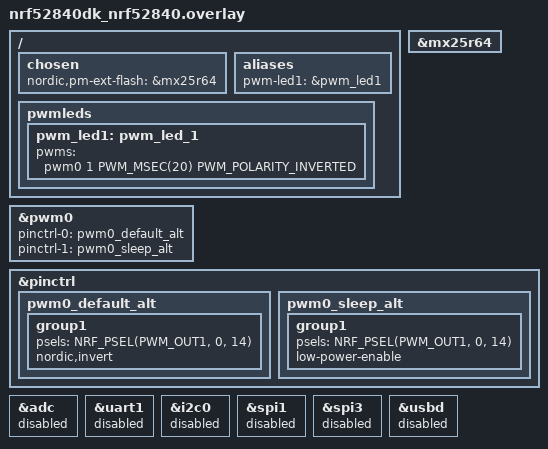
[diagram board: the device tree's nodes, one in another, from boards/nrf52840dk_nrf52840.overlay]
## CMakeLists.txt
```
#
#  Copyright (c) 2025 Nordic Semiconductor ASA
#
#  SPDX-License-Identifier: LicenseRef-Nordic-5-Clause
#


cmake_minimum_required(VERSION 3.20.0)

find_package(Zephyr HINTS $ENV{ZEPHYR_BASE})

project(matter-closure)

# Enable GNU STD support.
include(${ZEPHYR_CONNECTEDHOMEIP_MODULE_DIR}/config/nrfconnect/app/enable-gnu-std.cmake)

# NORDIC SDK APP START

# Include all source files that are located in the Matter common directory.
include(${ZEPHYR_NRF_MODULE_DIR}/samples/matter/common/cmake/source_common.cmake)

# Include Data Model utils
include(${ZEPHYR_NRF_MODULE_DIR}/samples/matter/common/cmake/data_model.cmake)

include(${ZEPHYR_NRF_MODULE_DIR}/samples/matter/common/cmake/zap_helpers.cmake)
ncs_get_zap_parent_dir(ZAP_PARENT_DIR)

target_include_directories(app PRIVATE
  src
  ${ZEPHYR_NRF_MODULE_DIR}/samples/matter/common/src/util
  ${ZAP_PARENT_DIR}
)

target_sources(app PRIVATE
  src/app_task.cpp
  src/main.cpp
  src/closure_manager.cpp
  src/closure_control_endpoint.cpp
  src/garage_door_impl.cpp
  src/persistent_percent.cpp
)

ncs_configure_data_model()
# NORDIC SDK APP END
```

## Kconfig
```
#
# Copyright (c) 2025 Nordic Semiconductor
#
# SPDX-License-Identifier: LicenseRef-Nordic-5-Clause
#
mainmenu "Matter nRF Connect Closure Example Application"

# Sample configuration used for Thread networking
if OPENTHREAD

choice OPENTHREAD_NORDIC_LIBRARY_CONFIGURATION
	default OPENTHREAD_NORDIC_LIBRARY_FTD
endchoice

choice OPENTHREAD_DEVICE_TYPE
	default OPENTHREAD_FTD
endchoice

endif # OPENTHREAD

config CHIP_WIFI
	default y if SHIELD_NRF7002EB2
	select DEPRECATED if SOC_SERIES_NRF53

source "$(ZEPHYR_CONNECTEDHOMEIP_MODULE_DIR)/config/nrfconnect/chip-module/Kconfig.features"
source "$(ZEPHYR_CONNECTEDHOMEIP_MODULE_DIR)/config/nrfconnect/chip-module/Kconfig.defaults"
source "$(ZEPHYR_NRF_MODULE_DIR)/samples/matter/common/src/Kconfig"
source "Kconfig.zephyr"
```

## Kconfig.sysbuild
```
#
# Copyright (c) 2025 Nordic Semiconductor ASA
#
# SPDX-License-Identifier: LicenseRef-Nordic-5-Clause
#

#### Radio core selection
config NRF_DEFAULT_IPC_RADIO
	default y

# Enable IEEE802.15.4 serialization to network core
# This config automatically pulls in the `overlay-802154.conf` in the ipc_radio image
config NETCORE_IPC_RADIO_IEEE802154
	default y if SOC_SERIES_NRF53

# Enable Bluetooth serialization to network core
# This config automatically pulls in the `overlay-bt_hci_ipc.conf` in the ipc_radio image
config NETCORE_IPC_RADIO_BT_HCI_IPC
	default y if SOC_SERIES_NRF53

#### Bootloader
choice BOOTLOADER
	default BOOTLOADER_MCUBOOT
endchoice

if BOOTLOADER_MCUBOOT

#### DFU multi-image support
config DFU_MULTI_IMAGE_PACKAGE_BUILD
	default y

config DFU_MULTI_IMAGE_PACKAGE_APP
	default y

#### DFU network core configuration
if SOC_SERIES_NRF53

choice MCUBOOT_MODE
	default MCUBOOT_MODE_OVERWRITE_ONLY
endchoice

choice BOOT_SIGNATURE_TYPE
	default BOOT_SIGNATURE_TYPE_RSA
endchoice

config SECURE_BOOT_NETCORE
	default y

config NETCORE_APP_UPDATE
	default y

config DFU_MULTI_IMAGE_PACKAGE_NET
	default y

config MCUBOOT_NRF53_MULTI_IMAGE_UPDATE
	default y if NETCORE_APP_UPDATE

endif # SOC_SERIES_NRF53

endif # BOOTLOADER_MCUBOOT

#### Enable generating factory data
config MATTER_FACTORY_DATA_GENERATE
	default y

source "share/sysbuild/Kconfig"
```

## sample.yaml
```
sample:
  description: Matter Closure sample
  name: Matter Closure
common:
  tags:
    - sysbuild
    - ci_samples_matter
tests:
  sample.matter.closure.debug:
    sysbuild: true
    build_only: true
    integration_platforms:
      - nrf54l15dk/nrf54l15/cpuapp
    platform_allow:
      - nrf52840dk/nrf52840
      - nrf5340dk/nrf5340/cpuapp
      - nrf54l15dk/nrf54l15/cpuapp
      - nrf54lm20dk/nrf54lm20b/cpuapp
      - nrf54lm20dk/nrf54lm20a/cpuapp
  sample.matter.closure.release:
    sysbuild: true
    build_only: true
    extra_args:
      - FILE_SUFFIX=release
    integration_platforms:
      - nrf54l15dk/nrf54l15/cpuapp
    platform_allow:
      - nrf52840dk/nrf52840
      - nrf5340dk/nrf5340/cpuapp
      - nrf54l15dk/nrf54l15/cpuapp
      - nrf54lm20dk/nrf54lm20b/cpuapp
      - nrf54lm20dk/nrf54lm20a/cpuapp
  sample.matter.closure.nrf7002eb2.debug:
    sysbuild: true
    build_only: true
    extra_args:
      - closure_SHIELD=nrf7002eb2
      - SB_CONFIG_WIFI_NRF70=y
    integration_platforms:
      - nrf54lm20dk/nrf54lm20b/cpuapp
    platform_allow:
      - nrf54lm20dk/nrf54lm20b/cpuapp
      - nrf54lm20dk/nrf54lm20a/cpuapp
  sample.matter.closure.nrf7002eb2.release:
    sysbuild: true
    build_only: true
    extra_args:
      - FILE_SUFFIX=release
      - SB_CONFIG_BOOTLOADER_MCUBOOT=y
      - closure_SHIELD=nrf7002eb2
      - SB_CONFIG_WIFI_NRF70=y
    integration_platforms:
      - nrf54lm20dk/nrf54lm20b/cpuapp
    platform_allow:
      - nrf54lm20dk/nrf54lm20b/cpuapp
      - nrf54lm20dk/nrf54lm20a/cpuapp
  sample.matter.closure.release.internal:
    sysbuild: true
    build_only: true
    extra_args:
      - FILE_SUFFIX=internal
      - closure_EXTRA_CONF_FILE=prj_release.conf
    integration_platforms:
      - nrf54lm20dk/nrf54lm20b/cpuapp
      - nrf54lm20dk/nrf54lm20a/cpuapp
    platform_allow:
      - nrf54lm20dk/nrf54lm20b/cpuapp
      - nrf54lm20dk/nrf54lm20a/cpuapp
```

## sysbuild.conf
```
#
# Copyright (c) 2025 Nordic Semiconductor
#
# SPDX-License-Identifier: LicenseRef-Nordic-5-Clause
#

SB_CONFIG_MATTER=y
```

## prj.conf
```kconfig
#
# Copyright (c) 2025 Nordic Semiconductor ASA
#
# SPDX-License-Identifier: LicenseRef-Nordic-5-Clause
#

# This sample uses Kconfig.defaults to set options common for all
# samples. This file should contain only options specific for this sample
# or overrides of default values.

# Enable CHIP
CONFIG_CHIP=y
CONFIG_CHIP_PROJECT_CONFIG="src/chip_project_config.h"
CONFIG_CHIP_DEVICE_PRODUCT_NAME="Matter Closure"

# Configure ZAP file name
CONFIG_NCS_SAMPLE_MATTER_ZAP_FILE_PATH="${APPLICATION_CONFIG_DIR}/src/default_zap/closure.zap"

# 32768 == 0x8000 (example Product ID added temporaly,
# but it must be changed with proper PID from the list:
# https://github.com/project-chip/connectedhomeip/blob/482e6fd03196a6de45465a90003947ef4b86e0b1/docs/examples/discussion/PID_allocation_for_example_apps.md)
CONFIG_CHIP_DEVICE_PRODUCT_ID=32768
CONFIG_STD_CPP17=y

# Enable Matter pairing automatically on application start.
CONFIG_CHIP_ENABLE_PAIRING_AUTOSTART=y

# Enable Matter extended announcement and increase duration to 1 hour.
CONFIG_CHIP_BLE_EXT_ADVERTISING=y
CONFIG_CHIP_BLE_ADVERTISING_DURATION=60

# Add support for LEDs and buttons on Nordic development kits
CONFIG_DK_LIBRARY=y
CONFIG_PWM=y

# Bluetooth Low Energy configuration
CONFIG_BT_DEVICE_NAME="MatterClosure"

# Other settings
CONFIG_THREAD_NAME=y
CONFIG_MPU_STACK_GUARD=y
CONFIG_RESET_ON_FATAL_ERROR=n
CONFIG_CHIP_LIB_SHELL=y
CONFIG_NCS_SAMPLE_MATTER_TEST_SHELL=y

# Disable NFC onboarding
CONFIG_CHIP_NFC_ONBOARDING_PAYLOAD=n

# Reduce application size
CONFIG_USE_SEGGER_RTT=n

#Enable Persistent Storage
CONFIG_NCS_SAMPLE_MATTER_PERSISTENT_STORAGE=y
```

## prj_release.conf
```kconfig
#
# Copyright (c) 2025 Nordic Semiconductor ASA
#
# SPDX-License-Identifier: LicenseRef-Nordic-5-Clause
#

# This sample uses Kconfig.defaults to set options common for all
# samples. This file should contain only options specific for this sample
# or overrides of default values.

# Enable CHIP
CONFIG_CHIP=y
CONFIG_CHIP_PROJECT_CONFIG="src/chip_project_config.h"
CONFIG_CHIP_DEVICE_PRODUCT_NAME="Matter Closure"

# Configure ZAP file name
CONFIG_NCS_SAMPLE_MATTER_ZAP_FILE_PATH="${APPLICATION_CONFIG_DIR}/src/default_zap/closure.zap"

# 32768 == 0x8000 (example Product ID added temporaly,
# but it must be changed with proper PID from the list:
# https://github.com/project-chip/connectedhomeip/blob/482e6fd03196a6de45465a90003947ef4b86e0b1/docs/examples/discussion/PID_allocation_for_example_apps.md)
CONFIG_CHIP_DEVICE_PRODUCT_ID=32768
CONFIG_STD_CPP17=y

# Enable Matter pairing automatically on application start.
CONFIG_CHIP_ENABLE_PAIRING_AUTOSTART=y

# Enable Matter extended announcement and increase duration to 1 hour.
CONFIG_CHIP_BLE_EXT_ADVERTISING=y
CONFIG_CHIP_BLE_ADVERTISING_DURATION=60

# Add support for LEDs and buttons on Nordic development kits
CONFIG_DK_LIBRARY=y
CONFIG_PWM=y

# Bluetooth Low Energy configuration
CONFIG_BT_DEVICE_NAME="MatterClosure"

# Enable system reset on fatal error
CONFIG_RESET_ON_FATAL_ERROR=y

# Disable all debug features
CONFIG_USE_SEGGER_RTT=n
CONFIG_SHELL=n
CONFIG_OPENTHREAD_SHELL=n
CONFIG_CHIP_LIB_SHELL=n
CONFIG_CONSOLE=n
CONFIG_UART_CONSOLE=n
CONFIG_SERIAL=n
CONFIG_LOG=n
CONFIG_LOG_MODE_MINIMAL=n
CONFIG_ASSERT_VERBOSE=n
CONFIG_ASSERT_NO_FILE_INFO=y
CONFIG_PRINTK=n
CONFIG_PRINTK_SYNC=n
CONFIG_THREAD_NAME=n
CONFIG_BOOT_BANNER=n

# Disable NFC onboarding
CONFIG_CHIP_NFC_ONBOARDING_PAYLOAD=n

# Enable Factory Data feature
CONFIG_CHIP_FACTORY_DATA=y
CONFIG_CHIP_FACTORY_DATA_BUILD=y

# Enable Watchdog
CONFIG_NCS_SAMPLE_MATTER_WATCHDOG=y

# Enable LTO to decrease the flash usage.
CONFIG_LTO=y
CONFIG_ISR_TABLES_LOCAL_DECLARATION=y

#Enable Persistent Storage
CONFIG_NCS_SAMPLE_MATTER_PERSISTENT_STORAGE=y
```

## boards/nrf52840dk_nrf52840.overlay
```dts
/*
 * Copyright (c) 2025 Nordic Semiconductor ASA
 *
 * SPDX-License-Identifier: LicenseRef-Nordic-5-Clause
 */

#include <samples/matter/nrf52840_partitions.dtsi>

/ {
	chosen {
		nordic,pm-ext-flash = &mx25r64;
	};

	aliases {
		pwm-led1 = &pwm_led1;
	};

	pwmleds {
		pwm_led1: pwm_led_1 {
			pwms = <&pwm0 1 PWM_MSEC(20) PWM_POLARITY_INVERTED>;
		};
	};
};

&mx25r64 {
	status = "okay";
};

&pwm0 {
	pinctrl-0 = <&pwm0_default_alt>;
	pinctrl-1 = <&pwm0_sleep_alt>;
	pinctrl-names = "default", "sleep";
};

&pinctrl {
	pwm0_default_alt: pwm0_default_alt {
		group1 {
			psels = <NRF_PSEL(PWM_OUT1, 0, 14)>;
			nordic,invert;
		};
	};

	pwm0_sleep_alt: pwm0_sleep_alt {
		group1 {
			psels = <NRF_PSEL(PWM_OUT1, 0, 14)>;
			low-power-enable;
		};
	};
};

/* Disable unused peripherals to reduce power consumption */
&adc {
	status = "disabled";
};

&uart1 {
	status = "disabled";
};

&i2c0 {
	status = "disabled";
};

&spi1 {
	status = "disabled";
};

&spi3 {
	status = "disabled";
};

&usbd {
	status = "disabled";
};
```

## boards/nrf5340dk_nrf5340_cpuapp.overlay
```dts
/*
 * Copyright (c) 2025 Nordic Semiconductor ASA
 *
 * SPDX-License-Identifier: LicenseRef-Nordic-5-Clause
 */

#include <samples/matter/nrf5340_cpuapp_partitions.dtsi>
#include <zephyr/dt-bindings/ipc_service/static_vrings.h>

/ {
	chosen {
		nordic,pm-ext-flash = &mx25r64;
	};

	aliases {
		pwm-led1 = &pwm_led1;
	};

	pwmleds {
		compatible = "pwm-leds";

		pwm_led1: pwm_led_1 {
			pwms = <&pwm0 1 PWM_MSEC(20) PWM_POLARITY_INVERTED>;
		};
	};
};

/* Set IPC thread priority to the highest value to not collide with other threads. */
&ipc0 {
	zephyr,priority = <0 PRIO_COOP>;
};

&mx25r64 {
	status = "okay";
};

&pwm0 {
	pinctrl-0 = <&pwm0_default_alt>;
	pinctrl-1 = <&pwm0_sleep_alt>;
	pinctrl-names = "default", "sleep";
};

&pinctrl {
	pwm0_default_alt: pwm0_default_alt {
		group1 {
			psels = <NRF_PSEL(PWM_OUT1, 0, 29)>;
			nordic,invert;
		};
	};

	pwm0_sleep_alt: pwm0_sleep_alt {
		group1 {
			psels = <NRF_PSEL(PWM_OUT1, 0, 29)>;
			low-power-enable;
		};
	};
};

/* Disable unused peripherals to reduce power consumption */
&adc {
	status = "disabled";
};

&i2c1 {
	status = "disabled";
};

&spi2 {
	status = "disabled";
};

&usbd {
	status = "disabled";
};
```

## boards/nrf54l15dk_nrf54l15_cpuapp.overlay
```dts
/*
 * Copyright (c) 2025 Nordic Semiconductor ASA
 *
 * SPDX-License-Identifier: LicenseRef-Nordic-5-Clause
 */

#include <samples/matter/nrf54l15_cpuapp_partitions.dtsi>

/ {
	chosen {
		nordic,pm-ext-flash = &mx25r64;
	};

	aliases {
		/* Configure PWM module for led1 (LED2 on the board) */
		pwm-led1 = &pwm_led1;

		/* Use watchdog wdt31 as the application watchdog */
		watchdog0 = &wdt31;
	};

	pwmleds {
		compatible = "pwm-leds";

		pwm_led1: pwm_led_1 {
			pwms = <&pwm20 1 PWM_MSEC(20) PWM_POLARITY_NORMAL>;
		};
	};
};

&mx25r64 {
	status = "okay";
};

&pwm20 {
	status = "okay";
	pinctrl-0 = <&pwm_default>;
	pinctrl-1 = <&pwm_sleep>;
	pinctrl-names = "default", "sleep";
};

&pinctrl {
	pwm_default: pwm_default {
		group1 {
			psels = <NRF_PSEL(PWM_OUT1, 1, 10)>, <NRF_PSEL(PWM_OUT2, 1, 14)>;
		};
	};

	pwm_sleep: pwm_sleep {
		group1 {
			psels = <NRF_PSEL(PWM_OUT1, 1, 10)>, <NRF_PSEL(PWM_OUT2, 1, 14)>;
			low-power-enable;
		};
	};
};

&wdt31 {
	status = "okay";
};
```

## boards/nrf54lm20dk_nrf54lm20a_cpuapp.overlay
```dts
/*
 * Copyright (c) 2025 Nordic Semiconductor ASA
 *
 * SPDX-License-Identifier: LicenseRef-Nordic-5-Clause
 */

#include <samples/matter/nrf54lm20_cpuapp_partitions.dtsi>

/ {
	chosen {
		nordic,pm-ext-flash = &mx25r64;
	};

	aliases {
		/* Use watchdog wdt31 as the application watchdog */
		watchdog0 = &wdt31;
		pwm-led1 = &pwm_led1;
	};

	pwmleds {
		compatible = "pwm-leds";

		pwm_led1: pwm_led_1 {
			pwms = <&pwm20 1 PWM_MSEC(20) PWM_POLARITY_NORMAL>;
		};
	};
};

&pwm20 {
	status = "okay";
	pinctrl-0 = <&pwm_default>;
	pinctrl-1 = <&pwm_sleep>;
	pinctrl-names = "default", "sleep";
};

&pinctrl {
	pwm_default: pwm_default {
		group1 {
			psels = <NRF_PSEL(PWM_OUT1, 1, 25)>;
		};
	};

	pwm_sleep: pwm_sleep {
		group1 {
			psels = <NRF_PSEL(PWM_OUT1, 1, 25)>;
			low-power-enable;
		};
	};
};

&mx25r64 {
	status = "okay";
};

&wdt31 {
	status = "okay";
};
```

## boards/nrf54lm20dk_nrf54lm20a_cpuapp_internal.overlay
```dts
/*
 * Copyright (c) 2025 Nordic Semiconductor ASA
 *
 * SPDX-License-Identifier: LicenseRef-Nordic-5-Clause
 */

#include <samples/matter/nrf54lm20_cpuapp_internal_partitions.dtsi>

/ {
	aliases {
		/* Use watchdog wdt31 as the application watchdog */
		watchdog0 = &wdt31;
		pwm-led1 = &pwm_led1;
	};

	pwmleds {
		compatible = "pwm-leds";

		pwm_led1: pwm_led_1 {
			pwms = <&pwm20 1 PWM_MSEC(20) PWM_POLARITY_NORMAL>;
		};
	};
};

&pwm20 {
	status = "okay";
	pinctrl-0 = <&pwm_default>;
	pinctrl-1 = <&pwm_sleep>;
	pinctrl-names = "default", "sleep";
};

&pinctrl {
	pwm_default: pwm_default {
		group1 {
			psels = <NRF_PSEL(PWM_OUT1, 1, 25)>;
		};
	};

	pwm_sleep: pwm_sleep {
		group1 {
			psels = <NRF_PSEL(PWM_OUT1, 1, 25)>;
			low-power-enable;
		};
	};
};

&wdt31 {
	status = "okay";
};
```

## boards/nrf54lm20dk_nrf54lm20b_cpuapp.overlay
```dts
/*
 * Copyright (c) 2026 Nordic Semiconductor ASA
 *
 * SPDX-License-Identifier: LicenseRef-Nordic-5-Clause
 */

#include <samples/matter/nrf54lm20_cpuapp_partitions.dtsi>

/ {
	chosen {
		nordic,pm-ext-flash = &mx25r64;
	};

	aliases {
		/* Use watchdog wdt31 as the application watchdog */
		watchdog0 = &wdt31;
		pwm-led1 = &pwm_led1;
	};

	pwmleds {
		compatible = "pwm-leds";

		pwm_led1: pwm_led_1 {
			pwms = <&pwm20 1 PWM_MSEC(20) PWM_POLARITY_NORMAL>;
		};
	};
};

&pwm20 {
	status = "okay";
	pinctrl-0 = <&pwm_default>;
	pinctrl-1 = <&pwm_sleep>;
	pinctrl-names = "default", "sleep";
};

&pinctrl {
	pwm_default: pwm_default {
		group1 {
			psels = <NRF_PSEL(PWM_OUT1, 1, 25)>;
		};
	};

	pwm_sleep: pwm_sleep {
		group1 {
			psels = <NRF_PSEL(PWM_OUT1, 1, 25)>;
			low-power-enable;
		};
	};
};

&mx25r64 {
	status = "okay";
};

&wdt31 {
	status = "okay";
};
```

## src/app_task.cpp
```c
/*
 * Copyright (c) 2025 Nordic Semiconductor ASA
 *
 * SPDX-License-Identifier: LicenseRef-Nordic-5-Clause
 */

#include "app_task.h"

#include "app/matter_init.h"
#include "app/task_executor.h"
#include "board/board.h"
#include "closure_control_endpoint.h"
#include "closure_manager.h"
#include "clusters/identify.h"

#include "lib/core/CHIPError.h"
#include "lib/support/CodeUtils.h"
#include <app-common/zap-generated/ids/Attributes.h>
#include <app-common/zap-generated/ids/Clusters.h>
#include <app/data-model/Nullable.h>
#include <app/util/attribute-storage.h>
#include <setup_payload/OnboardingCodesUtil.h>

#include <persistent_storage/persistent_storage.h>

#include <zephyr/logging/log.h>

LOG_MODULE_DECLARE(app, CONFIG_CHIP_APP_LOG_LEVEL);

using namespace ::chip;
using namespace ::chip::app;
using namespace ::chip::DeviceLayer;
using namespace chip::app::Clusters::Descriptor;

namespace
{
const struct pwm_dt_spec sPhysicalIndicatorPwmDevice = PWM_DT_SPEC_GET(DT_ALIAS(pwm_led1));

constexpr chip::EndpointId kClosureEndpoint = 1;

/* TODO: Add a custom identify delegate to handle the custom identify stop behavior according to the closure state */
Nrf::Matter::IdentifyCluster sIdentifyCluster(kClosureEndpoint);
} /* namespace */

AppTask::AppTask() : mPhysicalDevice(&sPhysicalIndicatorPwmDevice), mClosureManager(mPhysicalDevice, kClosureEndpoint)
{
}

CHIP_ERROR AppTask::Init()
{
	ReturnErrorOnFailure(Nrf::Matter::PrepareServer());

	if (!Nrf::GetBoard().Init()) {
		LOG_ERR("User interface initialization failed.");
		return CHIP_ERROR_INCORRECT_STATE;
	}

	ReturnErrorOnFailure(Nrf::Matter::RegisterEventHandler(Nrf::Board::DefaultMatterEventHandler, 0));

	ReturnErrorOnFailure(Nrf::Matter::StartServer());

	ReturnErrorOnFailure(sIdentifyCluster.Init());

	if (Nrf::GetPersistentStorage().NonSecureInit(&mRootNode) != Nrf::PSErrorCode::Success) {
		return CHIP_ERROR_PERSISTED_STORAGE_FAILED;
	}

	ReturnErrorOnFailure(mClosureManager.Init());
	return CHIP_NO_ERROR;
}

CHIP_ERROR AppTask::StartApp()
{
	ReturnErrorOnFailure(Init());

	while (true) {
		Nrf::DispatchNextTask();
	}

	return CHIP_NO_ERROR;
}
```

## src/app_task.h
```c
/*
 * Copyright (c) 2025 Nordic Semiconductor ASA
 *
 * SPDX-License-Identifier: LicenseRef-Nordic-5-Clause
 */
#pragma once
#include "closure_manager.h"
#include "garage_door_impl.h"
#include <persistent_storage/persistent_storage_common.h>

class AppTask {
public:
	AppTask();
	static AppTask &Instance()
	{
		static AppTask sAppTask;
		return sAppTask;
	}

	CHIP_ERROR Init();
	CHIP_ERROR StartApp();

private:
	constexpr static auto kAccessPrefix = "cs";
	Nrf::PersistentStorageNode mRootNode{ kAccessPrefix, strlen(kAccessPrefix) };
	GarageDoorImpl mPhysicalDevice;
	ClosureManager mClosureManager;
};
```

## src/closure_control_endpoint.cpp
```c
/*
 * Copyright (c) 2025 Nordic Semiconductor ASA
 *
 * SPDX-License-Identifier: LicenseRef-Nordic-5-Clause
 */

#include "closure_control_endpoint.h"
#include "closure_manager.h"
#include <app-common/zap-generated/attributes/Accessors.h>
#include <app-common/zap-generated/cluster-enums.h>
#include <app-common/zap-generated/cluster-objects.h>
#include <platform/CHIPDeviceLayer.h>
#include <protocols/interaction_model/StatusCode.h>
#include <zephyr/logging/log.h>

#ifdef CONFIG_NCS_SAMPLE_MATTER_TEST_EVENT_TRIGGERS
#include <event_triggers/event_triggers.h>
#endif

LOG_MODULE_DECLARE(closure_cntrl, CONFIG_CHIP_APP_LOG_LEVEL);

using namespace chip;
using namespace chip::app::Clusters::ClosureControl;

using Status = chip::Protocols::InteractionModel::Status;
using TargetPositionEnum = chip::app::Clusters::ClosureControl::TargetPositionEnum;
using ThreeLevelAutoEnum = chip::app::Clusters::Globals::ThreeLevelAutoEnum;
namespace
{

constexpr ElapsedS kDefaultCountdownTime = 30;

enum class ClosureControlTestEventTrigger : Nrf::Matter::TestEventTrigger::EventTriggerId {
	kMainStateIsError = 0x0104000000000000,
	kMainStateIsProtected = 0x0104000000000001,
	kMainStateIsDisengaged = 0x0104000000000002,
	kMainStateIsSetupRequired = 0x0104000000000003,
	kClearEvent = 0x0104000000000004,
};

} /* namespace */

Status ClosureControlDelegate::HandleCalibrateCommand()
{
	if (mManager == nullptr) {
		LOG_ERR("No manager bound to ClosureControlDelegate");
		return Status::Failure;
	}
	return mManager->OnCalibrateCommand();
}

Status ClosureControlDelegate::HandleMoveToCommand(const chip::Optional<TargetPositionEnum> &position,
						   const chip::Optional<bool> &latch,
						   const chip::Optional<ThreeLevelAutoEnum> &speed)
{
	if (mManager == nullptr) {
		LOG_ERR("No manager bound to ClosureControlDelegate");
		return Status::Failure;
	}
	return mManager->OnMoveToCommand(position, latch, speed);
}

Status ClosureControlDelegate::HandleStopCommand()
{
	if (mManager == nullptr) {
		LOG_ERR("No manager bound to ClosureControlDelegate");
		return Status::Failure;
	}
	return mManager->OnStopCommand();
}

bool ClosureControlDelegate::IsReadyToMove()
{
	/* This function should return true if the closure is ready to move.
	   For now, we will return true. */
	return true;
}

ElapsedS ClosureControlDelegate::GetCalibrationCountdownTime()
{
	/* This function should return the calibration countdown time.
	   For now, we will return kDefaultCountdownTime. */
	return kDefaultCountdownTime;
}

ElapsedS ClosureControlDelegate::GetMovingCountdownTime()
{
	return mManager->GetMoveCountdownTime();
}

ElapsedS ClosureControlDelegate::GetWaitingForMotionCountdownTime()
{
	/* This function should return the waiting for motion countdown time.
	   For now, we will return kDefaultCountdownTime. */
	return kDefaultCountdownTime;
}

CHIP_ERROR ClosureControlEndpoint::Init()
{
	ClusterConformance conformance;
	conformance.FeatureMap().Set(Feature::kPositioning).Set(Feature::kSpeed).Set(Feature::kVentilation);
	conformance.OptionalAttributes().Set<Attributes::CountdownTime::Id>();

	ClusterInitParameters initParams;

	ReturnErrorOnFailure(mInterface.Init(conformance, initParams));
	mDelegate.SetCluster(&mInterface.Cluster());

#ifdef CONFIG_NCS_SAMPLE_MATTER_TEST_EVENT_TRIGGERS
	ReturnErrorOnFailure(Nrf::Matter::TestEventTrigger::Instance().RegisterTestEventTriggerHandler(&mDelegate));
#endif

	return CHIP_NO_ERROR;
}

CHIP_ERROR
ClosureControlEndpoint::WriteAllAttributes(const MainStateEnum &mainState,
					   const GenericOverallCurrentState &currentState,
					   const chip::app::DataModel::Nullable<GenericOverallTargetState> &targetState)
{
	auto &cluster = mInterface.Cluster();
	chip::DeviceLayer::StackLock lock;
	ReturnErrorOnFailure(cluster.SetMainState(mainState));
	ReturnErrorOnFailure(cluster.SetOverallCurrentState(chip::app::DataModel::MakeNullable(currentState)));
	ReturnErrorOnFailure(cluster.SetCountdownTimeFromDelegate(mDelegate.GetMovingCountdownTime()));

	if (!targetState.IsNull()) {
		ReturnErrorOnFailure(cluster.SetOverallTargetState(targetState));
	}

	return CHIP_NO_ERROR;
}

CHIP_ERROR
ClosureControlEndpoint::OnMovementStopped(const MainStateEnum &mainState,
					  const GenericOverallCurrentState &currentState,
					  const chip::app::DataModel::Nullable<GenericOverallTargetState> &targetState)
{
	ReturnErrorOnFailure(WriteAllAttributes(mainState, currentState, targetState));
	ReturnErrorOnFailure(GetLogic().GenerateMovementCompletedEvent());
	return CHIP_NO_ERROR;
}

CHIP_ERROR
ClosureControlEndpoint::OnMovementUpdate(const MainStateEnum &mainState, const GenericOverallCurrentState &currentState,
					 const chip::app::DataModel::Nullable<GenericOverallTargetState> &targetState)
{
	return WriteAllAttributes(mainState, currentState, targetState);
}

CHIP_ERROR ClosureControlDelegate::HandleEventTrigger(uint64_t eventTrigger)
{
	eventTrigger = clearEndpointInEventTrigger(eventTrigger);

	auto trigger = static_cast<ClosureControlTestEventTrigger>(eventTrigger);
	auto *cluster = GetCluster();
	VerifyOrReturnError(cluster != nullptr, CHIP_ERROR_INCORRECT_STATE);

	switch (trigger) {
	case ClosureControlTestEventTrigger::kMainStateIsError:
		ReturnErrorOnFailure(cluster->SetMainState(MainStateEnum::kError));
		ReturnErrorOnFailure(cluster->AddErrorToCurrentErrorList(ClosureErrorEnum::kBlockedBySensor));
		break;
	case ClosureControlTestEventTrigger::kMainStateIsProtected:
		ReturnErrorOnFailure(cluster->SetMainState(MainStateEnum::kProtected));
		break;
	case ClosureControlTestEventTrigger::kMainStateIsDisengaged:
		ReturnErrorOnFailure(cluster->SetMainState(MainStateEnum::kDisengaged));
		break;
	case ClosureControlTestEventTrigger::kMainStateIsSetupRequired:
		ReturnErrorOnFailure(cluster->SetMainState(MainStateEnum::kSetupRequired));
		break;
	case ClosureControlTestEventTrigger::kClearEvent:
		ReturnErrorOnFailure(cluster->SetMainState(MainStateEnum::kStopped));
		cluster->ClearCurrentErrorList();
		break;
	default:
		return CHIP_ERROR_INVALID_ARGUMENT;
	}
	return CHIP_NO_ERROR;
}
```

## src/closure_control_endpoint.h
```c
/*
 * Copyright (c) 2025 Nordic Semiconductor ASA
 *
 * SPDX-License-Identifier: LicenseRef-Nordic-5-Clause
 */

#pragma once

#include <app/clusters/closure-control-server/ClosureControlClusterDelegate.h>
#include <app/clusters/closure-control-server/ClosureControlClusterObjects.h>
#include <app/clusters/closure-control-server/ClosureControlCluster.h>
#include <app/clusters/closure-control-server/CodegenIntegration.h>

#include "pwm/pwm_device.h"
#include <app-common/zap-generated/cluster-objects.h>
#include <app/TestEventTriggerDelegate.h>
#include <lib/core/CHIPError.h>
#include <lib/core/DataModelTypes.h>
#include <protocols/interaction_model/StatusCode.h>

class ClosureManager;

/**
 * @class ClosureControlDelegate
 * @class Handles communication with the matter stack
 *
 * This class is responsible for comminicating with the Matter stack
 * It implements callback, such as HandleStopCommand, HandleMoveToCommand, HandleCalibrateCommand
 * That are called by Matter stack whenever a command is Invoked.
 * It also implements functions such as GetCalibrationCountdownTime, GetMovingCountdownTime,
 * GetWaitingForMotionCountdownTime That are called by Matter stack when it requires to know this information It mostly
 * forwards the callbacks, and receives data from ClosureManager
 * @param mManager Pointer to the ClosureManager
 * @param mCluster Pointer to the ClosureControlCluster (Matter stack implementation of ClosureControl)
 */
class ClosureControlDelegate : public chip::app::Clusters::ClosureControl::ClosureControlClusterDelegate,
			       public chip::TestEventTriggerHandler {
	using MainStateEnum = chip::app::Clusters::ClosureControl::MainStateEnum;
	using ThreeLevelAutoEnum = chip::app::Clusters::Globals::ThreeLevelAutoEnum;
	using GenericOverallCurrentState = chip::app::Clusters::ClosureControl::GenericOverallCurrentState;
	using GenericOverallTargetState = chip::app::Clusters::ClosureControl::GenericOverallTargetState;
	using TargetPositionEnum = chip::app::Clusters::ClosureControl::TargetPositionEnum;
	using ClosureControlCluster = chip::app::Clusters::ClosureControl::ClosureControlCluster;
	using ElapsedS = chip::ElapsedS;
	using EndpointId = chip::EndpointId;
	using Status = chip::Protocols::InteractionModel::Status;

public:
	ClosureControlDelegate() {}

	/* ClosureControlClusterDelegate overrides */
	Status HandleStopCommand() override;
	Status HandleMoveToCommand(const chip::Optional<TargetPositionEnum> &position,
				   const chip::Optional<bool> &latch,
				   const chip::Optional<ThreeLevelAutoEnum> &speed) override;
	Status HandleCalibrateCommand() override;
	void SetManager(ClosureManager *manager) { mManager = manager; }
	bool IsReadyToMove() override;
	ElapsedS GetCalibrationCountdownTime() override;
	ElapsedS GetMovingCountdownTime() override;
	ElapsedS GetWaitingForMotionCountdownTime() override;

	/* TestEventTriggerHandler overrides */
	CHIP_ERROR HandleEventTrigger(uint64_t eventTrigger) override;

	/* Delegate specific functions */
	void SetCluster(ClosureControlCluster *cluster) { mCluster = cluster; }
	ClosureControlCluster *GetCluster() const { return mCluster; }

private:
	ClosureManager *mManager = nullptr;
	ClosureControlCluster *mCluster = nullptr;
};

/**
 * @class ClosureControlEndpoint
 * @brief Represents a Closure Control cluster endpoint.
 *
 * This class encapsulates the logic and interfaces required to manage a Closure Control cluster
 * endpoint. It integrates the delegate and interface components for the endpoint.
 *
 * @param mEndpoint The endpoint ID associated with this Closure Control endpoint.
 * @param mDelegate The delegate instance for handling commands.
 * @param mInterface The interface for interacting with the cluster.
 */
class ClosureControlEndpoint {
public:
	using MainStateEnum = chip::app::Clusters::ClosureControl::MainStateEnum;
	using ThreeLevelAutoEnum = chip::app::Clusters::Globals::ThreeLevelAutoEnum;
	using GenericOverallCurrentState = chip::app::Clusters::ClosureControl::GenericOverallCurrentState;
	using GenericOverallTargetState = chip::app::Clusters::ClosureControl::GenericOverallTargetState;
	using TargetPositionEnum = chip::app::Clusters::ClosureControl::TargetPositionEnum;
	using ClosureControlCluster = chip::app::Clusters::ClosureControl::ClosureControlCluster;
	using Interface = chip::app::Clusters::ClosureControl::Interface;
	using ElapsedS = chip::ElapsedS;
	using EndpointId = chip::EndpointId;
	ClosureControlEndpoint(EndpointId endpoint) : mEndpoint(endpoint), mDelegate(), mInterface(mEndpoint, mDelegate) {}
	/**
	 * @brief Updates all the attributes in the Matter Stack
	 *
	 * @param mainState new MainState
	 * @param currentState newCurrentState
	 * @param targetState newTargetState
	 *
	 * @return CHIP_ERROR indicating the result of the operation
	 */

	CHIP_ERROR WriteAllAttributes(const MainStateEnum &mainState, const GenericOverallCurrentState &currentState,
				      const chip::app::DataModel::Nullable<GenericOverallTargetState> &targetState);
	/**
	 * @brief Initializes the ClosureControlEndpoint instance.
	 *
	 * @return CHIP_ERROR indicating the result of the initialization.
	 */
	CHIP_ERROR Init();

	/**
	 * @brief Retrieves the delegate associated with this Closure Control endpoint.
	 *
	 * @return Reference to the ClosureControlDelegate instance.
	 */
	ClosureControlDelegate &GetDelegate() { return mDelegate; }

	/**
	 * @brief Returns a reference to the ClosureControlCluster instance associated with this object.
	 *
	 * @return ClosureControlCluster& Reference to the underlying cluster object.
	 */
	ClosureControlCluster &GetLogic() { return mInterface.Cluster(); }

	CHIP_ERROR OnMovementStopped(const MainStateEnum &mainState, const GenericOverallCurrentState &currentState,
				     const chip::app::DataModel::Nullable<GenericOverallTargetState> &targetState);

	CHIP_ERROR OnMovementUpdate(const MainStateEnum &mainState, const GenericOverallCurrentState &currentState,
				    const chip::app::DataModel::Nullable<GenericOverallTargetState> &targetState);

private:
	EndpointId mEndpoint = chip::kInvalidEndpointId;
	ClosureControlDelegate mDelegate;
	Interface mInterface;
};
```

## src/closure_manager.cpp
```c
/*
 * Copyright (c) 2025 Nordic Semiconductor ASA
 *
 * SPDX-License-Identifier: LicenseRef-Nordic-5-Clause
 */

#include "closure_manager.h"
#include "closure_control_endpoint.h"

#include <app-common/zap-generated/cluster-objects.h>
#include <app/util/attribute-storage.h>
#include <dk_buttons_and_leds.h>
#include <platform/CHIPDeviceLayer.h>

#include <app-common/zap-generated/attributes/Accessors.h>

#include <zephyr/kernel.h>
#include <zephyr/logging/log.h>

#include "physical_device.h"

#include "finite_map.h"

LOG_MODULE_DECLARE(closure_manager, CONFIG_CHIP_APP_LOG_LEVEL);

using namespace chip;
using namespace chip::app;
using namespace chip::DeviceLayer;
using namespace chip::app::Clusters;
using namespace chip::app::Clusters::ClosureControl;
using namespace chip::app::Clusters::Globals;

namespace
{
/* If you plan to dynamically populate the maps change the ExactPos2Enum function to support that */
constexpr Nrf::FiniteMap<TargetPositionEnum, uint16_t, 4> sPositionMapTarget = { {
	{ TargetPositionEnum::kMoveToFullyClosed, 10000 },
	{ TargetPositionEnum::kMoveToFullyOpen, 0 },
	{ TargetPositionEnum::kMoveToSignaturePosition, 4000 },
	{ TargetPositionEnum::kMoveToVentilationPosition, 8000 },
} };

constexpr Nrf::FiniteMap<CurrentPositionEnum, uint16_t, 4> sPositionMapCurr = { {
	{ CurrentPositionEnum::kFullyClosed, 10000 },
	{ CurrentPositionEnum::kFullyOpened, 0 },
	{ CurrentPositionEnum::kOpenedAtSignature, 4000 },
	{ CurrentPositionEnum::kOpenedForVentilation, 8000 },
} };

constexpr Nrf::FiniteMap<ThreeLevelAutoEnum, uint16_t, 4> sSpeedMap = { {
	{ ThreeLevelAutoEnum::kLow, 1000 },
	{ ThreeLevelAutoEnum::kMedium, 2500 },
	{ ThreeLevelAutoEnum::kHigh, 5000 },
	{ ThreeLevelAutoEnum::kAuto, 2500 },
} };

constexpr uint32_t kCountdownTimeSeconds = 10;

CurrentPositionEnum ExactPos2Enum(uint16_t currPositionExact)
{
	/* This implementation assumes that the map is full (which it is) */
	for (auto &item : sPositionMapCurr.mMap) {
		if (currPositionExact == item.value) {
			return item.key;
		}
	}
	return CurrentPositionEnum::kPartiallyOpened;
}
} /* namespace */

ClosureManager::ClosureManager(IPhysicalDevice &device, chip::EndpointId closureEndpoint)
	: mPhysicalDevice(device), mClosureControlEndpoint(closureEndpoint), mClosureEndpoint(closureEndpoint)
{
	mMainState = MainStateEnum::kStopped;
	mCurrentState.position = chip::MakeOptional(CurrentPositionEnum::kFullyOpened);
	mCurrentState.speed = chip::MakeOptional(ThreeLevelAutoEnum::kAuto);

	/* After the reboot data target should be null. */
	mTargetState.SetNull();
}

CHIP_ERROR ClosureManager::Init()
{
	mPhysicalDevice.SetObserver(this);
	ReturnErrorOnFailure(mPhysicalDevice.Init());
	DeviceLayer::StackLock lock;

	/* Closure endpoints initialization */
	mClosureControlEndpoint.GetDelegate().SetManager(this);
	ReturnErrorOnFailure(mClosureControlEndpoint.Init());

	/* Set Taglist for Closure endpoints */
	ReturnErrorOnFailure(SetTagList(mClosureEndpoint, mPhysicalDevice.GetSemanticTagList()));

	ReturnErrorOnFailure(mClosureControlEndpoint.WriteAllAttributes(mMainState, mCurrentState, mTargetState));

	return CHIP_NO_ERROR;
}

chip::Protocols::InteractionModel::Status ClosureManager::OnCalibrateCommand()
{
	return chip::Protocols::InteractionModel::Status::UnsupportedCommand;
}

chip::Protocols::InteractionModel::Status ClosureManager::OnStopCommand()
{
	CHIP_ERROR stopErr = mPhysicalDevice.Stop();
	if (stopErr != CHIP_NO_ERROR) {
		LOG_ERR("Unable to stop movement, error code: %lx", static_cast<long>(stopErr.AsInteger()));
		return chip::Protocols::InteractionModel::Status::Failure;
	}
	return chip::Protocols::InteractionModel::Status::Success;
}

chip::Protocols::InteractionModel::Status
ClosureManager::OnMoveToCommand(const chip::Optional<TargetPositionEnum> position, const chip::Optional<bool> latch,
				const chip::Optional<ThreeLevelAutoEnum> speed)
{
	/* Currently we do not support latching. */
	if (mClosureControlEndpoint.GetLogic().GetFeatureMap().Has(ClosureControl::Feature::kMotionLatching) &&
	    latch.HasValue()) {
		return chip::Protocols::InteractionModel::Status::UnsupportedCommand;
	}

	/* Determine target position.
	 * If position argument is provided, use it and have target position as a fallback.
	 */
	chip::Optional<TargetPositionEnum> targetPosition = NullOptional;
	if (position.HasValue()) {
		targetPosition.SetValue(position.Value());
	} else if (!mTargetState.IsNull() && mTargetState.Value().position.HasValue() &&
		   !mTargetState.Value().position.Value().IsNull()) {
		targetPosition.SetValue(mTargetState.Value().position.Value().Value());
	}

	/* If we have a target position, initiate movement. */
	if (targetPosition.HasValue()) {
		auto pos = sPositionMapTarget.TryAt(targetPosition.Value());
		if (!pos.has_value()) {
			LOG_ERR("Target position not found in map");
			return chip::Protocols::InteractionModel::Status::ConstraintError;
		}

		auto spd = sSpeedMap.TryAt(speed.ValueOr(mCurrentState.speed.Value()));
		if (!spd.has_value()) {
			LOG_ERR("Speed value not found in map");
			return chip::Protocols::InteractionModel::Status::ConstraintError;
		}

		CHIP_ERROR moveErr = mPhysicalDevice.MoveTo(pos.value(), spd.value());
		if (moveErr != CHIP_NO_ERROR) {
			LOG_ERR("Unable to move to position, error code: %lx", static_cast<long>(moveErr.AsInteger()));
			return chip::Protocols::InteractionModel::Status::Failure;
		}

		mMainState = MainStateEnum::kMoving;
		mTargetState.SetNonNull(GenericOverallTargetState(
			targetPosition, NullOptional, MakeOptional(speed.ValueOr(mCurrentState.speed.Value()))));
		mCurrentState.secureState.SetNonNull(false);
	}

	mCurrentState.speed.SetValue(speed.ValueOr(mCurrentState.speed.ValueOr(ThreeLevelAutoEnum::kAuto)));

	auto err = mClosureControlEndpoint.WriteAllAttributes(mMainState, mCurrentState, mTargetState);
	if (err != CHIP_NO_ERROR) {
		LOG_ERR("Unable to update attributes on move, error code: %lx", static_cast<long>(err.AsInteger()));
		return chip::Protocols::InteractionModel::Status::Failure;
	}
	return chip::Protocols::InteractionModel::Status::Success;
}

void ClosureManager::OnMovementStopped(uint16_t currentPosition)
{
	mCurrentState.position = MakeOptional(ExactPos2Enum(currentPosition));
	mMainState = MainStateEnum::kStopped;
	mMoveCountdownTime = 0;

	auto currPosition = sPositionMapCurr.TryAt(CurrentPositionEnum::kFullyClosed);
	if (currPosition.has_value() && currentPosition == currPosition.value()) {
		mCurrentState.secureState.SetNonNull(true);
	}

	if (!mTargetState.IsNull() && mTargetState.Value().position.HasValue()) {
		auto targetPosOpt = sPositionMapTarget.TryAt(mTargetState.Value().position.Value().Value());
		if (targetPosOpt.has_value() && targetPosOpt.value() == currentPosition) {
			mTargetState.SetNull();
		}
	}

	auto err = mClosureControlEndpoint.OnMovementStopped(mMainState, mCurrentState, mTargetState);
	if (err != CHIP_NO_ERROR) {
		LOG_ERR("Unable to update attributes for closureControlEndpoint after stop, error code: %lx",
			static_cast<long>(err.AsInteger()));
	} else {
		LOG_DBG("Attributes updated on movement stopped");
	}
}
void ClosureManager::OnSetup(uint16_t currentPosition)
{
	mCurrentState.position = MakeOptional(ExactPos2Enum(currentPosition));
}

void ClosureManager::OnMovementUpdate(uint16_t currentPosition, uint16_t timeLeft, bool justStarted)
{
	mCurrentState.position = MakeOptional(ExactPos2Enum(currentPosition));
	mMoveCountdownTime = timeLeft;
	auto err = mClosureControlEndpoint.OnMovementUpdate(mMainState, mCurrentState, mTargetState);
	if (err != CHIP_NO_ERROR) {
		LOG_ERR("Unable to update attributes for closureControlEndpoint while moving, error code: %lx",
			static_cast<long>(err.AsInteger()));
	}
}

/* Implementation of this callback is required by matter 1.5*/
void MatterClosureControlClusterServerAttributeChangedCallback(const chip::app::ConcreteAttributePath &attributePath)
{
	LOG_DBG("Closure Control cluster ID: " ChipLogFormatMEI, ChipLogValueMEI(attributePath.mAttributeId));
}
```

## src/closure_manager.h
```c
/*
 * Copyright (c) 2025 Nordic Semiconductor ASA
 *
 * SPDX-License-Identifier: LicenseRef-Nordic-5-Clause
 */

/*
 * @class ClosureManager
 * @brief Manages the initialization and operations related to closure and
 *        closure panel endpoints in the application.
 *
 * @note This class is part of the closure application example
 */

#pragma once

#include "board/board.h"
#include "closure_control_endpoint.h"
#include "physical_device.h"
#include "physical_device_observer.h"
#include <lib/core/DataModelTypes.h>
#include <zephyr/kernel.h>

/**
 * @class ClosureManager
 * @brief Main class responsible for handleing application logic
 * It receives callbacks from ClosureControlDelegate and uses ClosureControlEndpoint
 * to update attribues on the matter stack.
 * Using interface IPhysicalDevice it sends appropriate commands to the physical device
 * (in this sample implemented as a PWM led)
 */
class ClosureManager : public IPhysicalDeviceObserver {
	using TargetPositionEnum = chip::app::Clusters::ClosureControl::TargetPositionEnum;
	using MainStateEnum = chip::app::Clusters::ClosureControl::MainStateEnum;
	using ThreeLevelAutoEnum = chip::app::Clusters::Globals::ThreeLevelAutoEnum;
	using GenericOverallCurrentState = chip::app::Clusters::ClosureControl::GenericOverallCurrentState;
	using GenericOverallTargetState = chip::app::Clusters::ClosureControl::GenericOverallTargetState;
	using ElapsedS = chip::ElapsedS;

public:
	ClosureManager(IPhysicalDevice &device, chip::EndpointId closureEndpoint);

	CHIP_ERROR Init();

	/**
	 * @brief Handles the Calibrate command for the Closure.
	 *
	 *
	 * @return chip::Protocols::InteractionModel::Status Status of the command handling operation.
	 */
	chip::Protocols::InteractionModel::Status OnCalibrateCommand();

	/**
	 * @brief Handles the MoveTo command for the Closure.
	 *
	 * This method processes the MoveTo command, which is used to initiate a motion action
	 * for a closure.
	 *
	 * @param position Optional target position for the closure device.
	 * @param latch Optional flag indicating whether the closure should latch after moving.
	 * @param speed Optional speed setting for the movement, represented as a ThreeLevelAutoEnum.
	 * @return chip::Protocols::InteractionModel::Status Status of the command handling operation.
	 */
	chip::Protocols::InteractionModel::Status OnMoveToCommand(const chip::Optional<TargetPositionEnum> position,
								  const chip::Optional<bool> latch,
								  const chip::Optional<ThreeLevelAutoEnum> speed);

	/**
	 * @brief Handles the Stop command for the Closure.
	 *
	 * This method processes the Stop command, which is used to stop an action for a closure.
	 *
	 * @return chip::Protocols::InteractionModel::Status
	 *         Returns Status::Success if the Stop command is handled successfully,
	 *         or an appropriate error status otherwise.
	 */
	chip::Protocols::InteractionModel::Status OnStopCommand();

	void OnMovementStopped(uint16_t currentPosition) override;
	void OnSetup(uint16_t currentPosition) override;
	void OnMovementUpdate(uint16_t currentPosition, uint16_t timeLeft, bool justStarted = false) override;

	ElapsedS GetMoveCountdownTime() { return mMoveCountdownTime; }

private:
	ElapsedS mMoveCountdownTime = 0;
	IPhysicalDevice &mPhysicalDevice;
	MainStateEnum mMainState;
	GenericOverallCurrentState mCurrentState;
	chip::app::DataModel::Nullable<GenericOverallTargetState> mTargetState;

	ClosureControlEndpoint mClosureControlEndpoint;
	const chip::EndpointId mClosureEndpoint;
};
```

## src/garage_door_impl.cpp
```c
/*
 * Copyright (c) 2025 Nordic Semiconductor ASA
 *
 * SPDX-License-Identifier: LicenseRef-Nordic-5-Clause
 */

#include "garage_door_impl.h"
#include "closure_manager.h"
#include <app-common/zap-generated/attributes/Accessors.h>
#include <zephyr/logging/log.h>

LOG_MODULE_DECLARE(app, CONFIG_CHIP_APP_LOG_LEVEL);

using namespace chip;
using namespace chip::app::Clusters::Descriptor::Structs;
using namespace chip::DeviceLayer;

static constexpr uint32_t kMoveIntervalMs = 100;

GarageDoorImpl::GarageDoorImpl(const pwm_dt_spec *spec) : mSpec(spec), mCurrentPosition("cp") {}

Span<const SemanticTagStruct::Type> GarageDoorImpl::GetSemanticTagList() const
{
	static SemanticTagStruct::Type kGarageDoorEndpointTagList[] = {
		{ .namespaceID = kNamespaceClosure,
		  .tag = kTagClosureGarageDoor,
		  .label = chip::MakeOptional(
			  chip::app::DataModel::Nullable<chip::CharSpan>("Closure.GarageDoor"_span)) }
	};
	return Span<const SemanticTagStruct::Type>(kGarageDoorEndpointTagList);
}

CHIP_ERROR GarageDoorImpl::Init()
{
	ReturnErrorOnFailure(mCurrentPosition.Load());
	mObserver->OnSetup(mCurrentPosition.Get());

	if (mPhysicalIndicator.Init(mSpec, 0, 255) != 0) {
		LOG_ERR("Cannot initialize the physical indicator");
		return CHIP_ERROR_INCORRECT_STATE;
	}
	uint8_t brightness =
		static_cast<uint8_t>((static_cast<uint32_t>(mCurrentPosition.Get()) * 255U + 5000U) / 10000U);
	mPhysicalIndicator.InitiateAction(Nrf::PWMDevice::LEVEL_ACTION, 0, &brightness);

	return CHIP_NO_ERROR;
}

CHIP_ERROR GarageDoorImpl::MoveTo(uint16_t position, uint16_t speed)
{
	LOG_DBG("Starting movement");
	mTargetPosition = position;
	mSpeed = speed;

	ReturnErrorOnFailure(
		SystemLayer().StartTimer(System::Clock::Milliseconds32(kMoveIntervalMs), TimerTimeoutCallback, this));
	mJustStarted = true;
	return CHIP_NO_ERROR;
}

CHIP_ERROR GarageDoorImpl::Stop()
{
	SystemLayer().CancelTimer(TimerTimeoutCallback, this);
	LOG_DBG("Movement stopped");
	mObserver->OnMovementStopped(mCurrentPosition.Get());
	ReturnErrorOnFailure(mCurrentPosition.Set(mCurrentPosition.Get(), true));
	return CHIP_NO_ERROR;
}

void GarageDoorImpl::TimerTimeoutCallback(System::Layer *systemLayer, void *appState)
{
	auto *self = static_cast<GarageDoorImpl *>(appState);
	VerifyOrReturn(self != nullptr);
	CHIP_ERROR err = self->HandleTimer();
	if (err != CHIP_NO_ERROR) {
		LOG_ERR("HandleTimer failed, chip error code: %lx", static_cast<long>(err.AsInteger()));
	}
}

CHIP_ERROR GarageDoorImpl::HandleTimer()
{
	bool finished = false;
	uint32_t movePerTick32 = (static_cast<uint32_t>(mSpeed) * kMoveIntervalMs) / 1000U;
	uint16_t movePerTick = static_cast<uint16_t>(std::min<uint32_t>(movePerTick32, UINT16_MAX));
	uint16_t distanceLeft = 0;

	if (mCurrentPosition.Get() <= mTargetPosition) {
		distanceLeft = mTargetPosition - mCurrentPosition.Get();
		if (movePerTick >= distanceLeft) {
			finished = true;
			ReturnErrorOnFailure(mCurrentPosition.Set(mTargetPosition));
		} else {
			ReturnErrorOnFailure(mCurrentPosition.Set(mCurrentPosition.Get() + movePerTick));
		}
	} else {
		distanceLeft = mCurrentPosition.Get() - mTargetPosition;
		if (movePerTick >= distanceLeft) {
			finished = true;
			ReturnErrorOnFailure(mCurrentPosition.Set(mTargetPosition));
		} else {
			ReturnErrorOnFailure(mCurrentPosition.Set(mCurrentPosition.Get() - movePerTick));
		}
	}
	uint8_t brightness =
		static_cast<uint8_t>((static_cast<uint32_t>(mCurrentPosition.Get()) * 255U + 5000U) / 10000U);

	mPhysicalIndicator.InitiateAction(Nrf::PWMDevice::LEVEL_ACTION, 0, &brightness);

	if (finished) {
		ReturnErrorOnFailure(Stop());
	} else {
		uint32_t timeLeftMs = (static_cast<uint32_t>(distanceLeft) * kMoveIntervalMs) / movePerTick;
		uint16_t timeLeftS = static_cast<uint16_t>((timeLeftMs + 999) / 1000); /*ceil*/
		mObserver->OnMovementUpdate(mCurrentPosition.Get(), timeLeftS, mJustStarted);
		mJustStarted = false;
		SystemLayer().StartTimer(System::Clock::Milliseconds32(kMoveIntervalMs), TimerTimeoutCallback, this)
			.Handle([&](CHIP_ERROR err) {
				LOG_ERR("Timer failed to restart, chip error code: %lx",
					static_cast<long>(err.AsInteger()));
			});
	}
	return CHIP_NO_ERROR;
}
```

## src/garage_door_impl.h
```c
/*
 * Copyright (c) 2025 Nordic Semiconductor ASA
 *
 * SPDX-License-Identifier: LicenseRef-Nordic-5-Clause
 */

#pragma once

#include "persistent_percent.h"
#include "physical_device.h"
#include "physical_device_observer.h"
#include "pwm/pwm_device.h"
#include <app/util/attribute-storage.h>
#include <platform/CHIPDeviceLayer.h>

/**
 * @class GarageDoorImpl
 * @brief Implementation of IPhysicalDevice using an LED
 */
class GarageDoorImpl : public IPhysicalDevice {
public:
	explicit GarageDoorImpl(const pwm_dt_spec *spec);

	CHIP_ERROR Init() override;
	CHIP_ERROR MoveTo(uint16_t position, uint16_t speed) override;
	CHIP_ERROR Stop() override;

	SemanticTagList GetSemanticTagList() const override;

private:
	/* Define the Namespace and Tag for the endpoint */
	constexpr static uint8_t kNamespaceClosure = 0x44;
	constexpr static uint8_t kTagClosureGarageDoor = 0x05;

	static void TimerTimeoutCallback(chip::System::Layer *systemLayer, void *appState);
	CHIP_ERROR HandleTimer();
	Nrf::PWMDevice mPhysicalIndicator;
	const pwm_dt_spec *mSpec;
	bool mJustStarted = false;
	uint16_t mSpeed;
	PersistentPercent mCurrentPosition;
	uint16_t mTargetPosition;
};
```

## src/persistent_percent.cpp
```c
/*
 * Copyright (c) 2025 Nordic Semiconductor ASA
 *
 * SPDX-License-Identifier: LicenseRef-Nordic-5-Clause
 */

#include "persistent_percent.h"

#include <cstdlib>
#include <cstring>
#include <persistent_storage/persistent_storage.h>
#include <platform/CHIPDeviceLayer.h>

#include <zephyr/logging/log.h>

LOG_MODULE_DECLARE(persistent_percent, CONFIG_CHIP_APP_LOG_LEVEL);

using namespace chip;
using namespace chip::DeviceLayer;

CHIP_ERROR PersistentPercent::Set(uint16_t newValue, bool forceStore)
{
	mValue = newValue;
	uint16_t rounded = RoundToStep(newValue);

	if (forceStore) {
		ReturnErrorOnFailure(Store(mValue));
	} else if (rounded != mStored) {
		ReturnErrorOnFailure(Store(rounded));
	}
	return CHIP_NO_ERROR;
}

CHIP_ERROR PersistentPercent::Store(uint16_t val)
{
	Nrf::PersistentStorageNode node{ mKey.c_str(), mKey.size() + 1 };
	auto err = Nrf::GetPersistentStorage().NonSecureStore(&node, &val, sizeof(val));

	if (err == Nrf::PSErrorCode::Success) {
		mStored = val;
		return CHIP_NO_ERROR;
	}
	return CHIP_ERROR_PERSISTED_STORAGE_FAILED;
}

CHIP_ERROR PersistentPercent::Load()
{
	Nrf::PersistentStorageNode node{ mKey.c_str(), mKey.size() + 1 };
	size_t outSize = 0;
	auto err = Nrf::GetPersistentStorage().NonSecureLoad(&node, &mValue, sizeof(mValue), outSize);

	if (err == Nrf::PSErrorCode::Success) {
		mStored = mValue;
		return CHIP_NO_ERROR;
	}

	/* Not found, store default value */
	return Store(mValue);
}

uint16_t PersistentPercent::RoundToStep(uint16_t v)
{
	uint16_t best = allowed[0];
	uint16_t bestDiff = std::abs((int)allowed[0] - (int)v);

	for (uint16_t a : allowed) {
		uint16_t diff = std::abs((int)a - (int)v);
		if (diff < bestDiff) {
			best = a;
			bestDiff = diff;
		}
	}
	return best;
}
```

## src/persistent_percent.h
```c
/*
 * Copyright (c) 2025 Nordic Semiconductor ASA
 *
 * SPDX-License-Identifier: LicenseRef-Nordic-5-Clause
 */

#pragma once

#include <cstdint>
#include <lib/core/CHIPError.h>
#include <string>

/**
 * Specialization for a persistent uint16_t that:
 * - Rounds to {0,2000,4000,6000,8000,10000}
 */
class PersistentPercent {
public:
	explicit PersistentPercent(const char *key, uint16_t defaultValue = 0) : mKey(key), mValue(defaultValue) {}

	uint16_t Get() const { return mValue; }
	CHIP_ERROR Set(uint16_t newValue, bool forceStore = false);

	CHIP_ERROR Load();

private:
	static constexpr uint16_t allowed[] = { 0, 2000, 4000, 6000, 8000, 10000 };
	uint16_t RoundToStep(uint16_t v);
	CHIP_ERROR Store(uint16_t val);

	std::string mKey;
	uint16_t mValue;
	uint16_t mStored;
};
```
